# m52363b register map
Vendor: Elmos Semiconductor SE; Series: Integrated Driver; File version: 1.0
Universal Smart LIN Motor Controller - medium power
CPU: CM23 r1p0, little endian, MPU, no FPU, VTOR, 2 interrupt priority bits, 13 interrupts
Registers are 16-bit, read-write, reset 0x0 unless marked. A register's access mark holds for its fields unless they carry their own. Offsets are from the block's base; lines under a group give offsets from that group; [hi:lo] are bit positions; {n}, {i} and the like mark numbered series; 'fields as' and 'values as' point back to an identical list; <NAME> marks a mode.

## Memory map
0x010002F8 ALT_BOOT_SIGNATURE size 0x8 — Location of customer specific alternative boot signature
0x40000000 WDOG size 0x100 — Watchdog module
0x40000200 CRC16 size 0x100 — General purpose CCITT-CRC-16 module
0x40000300 SFL_CTRL size 0x100 — Flash control module
0x40000600 CLOCK_CTRL size 0x100 — Clock control module
0x41000000 TIMER0 size 0x100 — Optional timer module
0x41000100 TIMER1 size 0x100 — Optional timer module
0x41000400 SYS_STATE size 0x100 — System state module
0x41000500 RESET_CTRL size 0x100 — Reset control module
0x45000010 MOD_SEC_S size 0x8 — This instance contains registers for (core system level) module secure access protection.
0x45000018 MOD_SEC_CORE_S size 0x8 — This instance contains registers for (core level) module secure access protection.
0x45000020 MOD_SECEXT size 0x8 — This instance contains registers for (core system level) module non-secure access protection
0x45000028 MOD_SECEXT_CORE size 0x8 — This instance contains registers for (core level) module non-secure access protection
0x45000100 DMA_SEC_CRC16 size 0x10 — This instance contains registers for (core system level) DMA access protection.
0x45000180 DMA_SEC_CORE_LIN size 0x10 — This instance contains registers for (core level) DMA access protection.
0x45000200 SEC_STATE size 0x10 — This instance contains registers for (core system level) DMA access error handling.
0x45000210 SEC_STATE_CORE size 0x10 — This instance contains registers for (core level) DMA access error handling.
0x45000220 SEC_VERSION size 0x10
0x50000000 GPIO size 0x100 — GPIO module
0x50000100 SWTIMER size 0x100 — SWTIMER module
0x50000200 HB size 0x100 — Half bridge control module
0x50000300 PWM size 0x100 — PWM module for half bridge control
0x50000400 ADC size 0x100 — ADC control module
0x50000500 SUP size 0x100 — Supply regulator control module
0x50000600 SPI size 0x100 — SPI module
0x50000700 CCT size 0x100 — Capture compare control module (SENT)
0x51000000 LINSCI size 0x100 — LINSCI module
0x51000100 LIN_CTRL size 0x40 — LIN_CTRL module

## Interrupts
0 RESET_CTRL
1 WDOG
3 TIMER0
4 TIMER1
5 GPIO
6 LINSCI
7 LIN_CTRL
8 SWTIMER
9 HB
10 ADC
11 SPI
12 CCT

## ALT_BOOT_SIGNATURE — Location of customer specific alternative boot signature
Base 0x010002F8
0x00 ALT_BOOT_SIGNATURE_L 32-bit ro reset 0xFFFFFFFF
  [31:0] val — val bitfield
0x04 ALT_BOOT_SIGNATURE_H 32-bit ro reset 0xFFFFFFFF
  [31:0] val — val bitfield

## WDOG — Watchdog module
Base 0x40000000
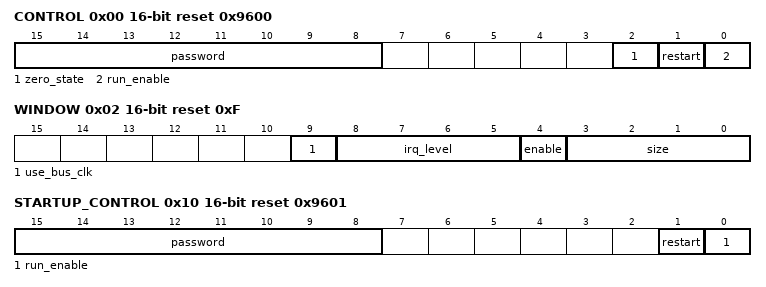
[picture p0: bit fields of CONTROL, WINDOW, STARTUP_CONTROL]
0x00 CONTROL reset 0x9600 (reset mask 0xFF05)
  [15:8] password — password bitfield
  [2] zero_state ro — zero_state bitfield
  [1] restart wo — restart bitfield
  [0] run_enable — run_enable bitfield
0x02 WINDOW reset 0xF
  [9] use_bus_clk — use_bus_clk bitfield
  [8:5] irq_level — irq_level bitfield
  [4] enable — enable bitfield
  [3:0] size — size bitfield
0x04 PRESCALER reset 0xFF
  [7:0] val — val bitfield
0x06 RELOAD reset 0xFFFF
  [15:0] val — val bitfield
0x08 COUNTER ro reset 0xFFFF
  [15:0] val — val bitfield
0x10 STARTUP_CONTROL reset 0x9601 (reset mask 0xFF01)
  [15:8] password — password bitfield
  [1] restart wo — restart bitfield
  [0] run_enable — run_enable bitfield
0x14 STARTUP_PRESCALER ro
  [7:0] val — val bitfield
0x16 STARTUP_RELOAD
  [15:0] val — val bitfield
0x18 STARTUP_COUNTER ro
  [15:0] val — val bitfield
0x20 STARTUP_COOKIE wo reset not defined
  [15:0] val — val bitfield
0x2C VERSION ro reset 0x2
  [15:0] version — version bitfield
0x30 IRQ_STATUS
  [0] evt_sanity — evt_sanity bitfield
0x34 IRQ_MASK
  [0] evt_sanity — evt_sanity bitfield
0x38 IRQ_VENABLE wo reset not defined
  [0] vno — vno bitfield
0x3A IRQ_VDISABLE wo reset not defined
  [0] vno — vno bitfield
0x3C IRQ_VMAX reset 0x1
  [0] vmax — vmax bitfield
0x3E IRQ_VNO reset 0x1
  [0] vno — vno bitfield
